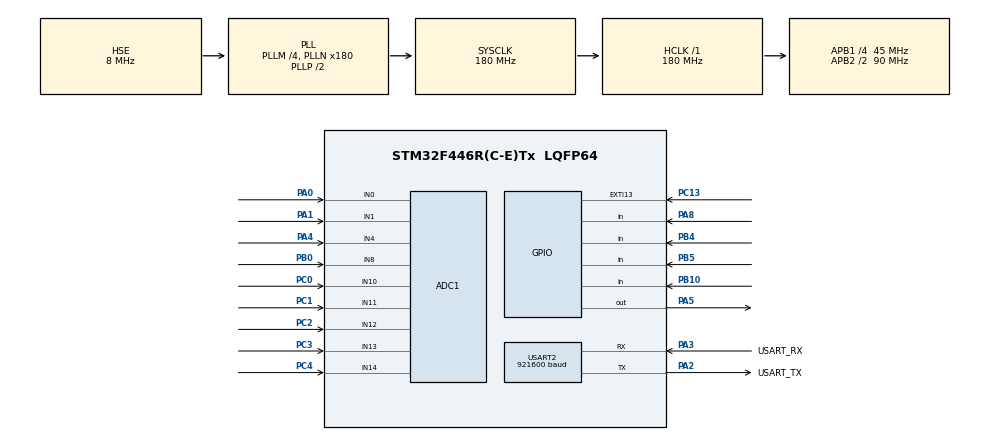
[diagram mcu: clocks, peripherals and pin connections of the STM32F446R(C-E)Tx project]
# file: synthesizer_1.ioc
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ADC1.Channel-0\#ChannelRegularConversion=ADC_CHANNEL_0
ADC1.Channel-1\#ChannelRegularConversion=ADC_CHANNEL_1
ADC1.Channel-2\#ChannelRegularConversion=ADC_CHANNEL_4
ADC1.Channel-3\#ChannelRegularConversion=ADC_CHANNEL_8
ADC1.Channel-4\#ChannelRegularConversion=ADC_CHANNEL_11
ADC1.Channel-5\#ChannelRegularConversion=ADC_CHANNEL_10
ADC1.Channel-6\#ChannelRegularConversion=ADC_CHANNEL_12
ADC1.Channel-7\#ChannelRegularConversion=ADC_CHANNEL_13
ADC1.Channel-8\#ChannelRegularConversion=ADC_CHANNEL_14
ADC1.NbrOfConversion=9
ADC1.NbrOfConversionFlag=1
ADC1.Rank-0\#ChannelRegularConversion=1
ADC1.Rank-1\#ChannelRegularConversion=2
ADC1.Rank-2\#ChannelRegularConversion=3
ADC1.Rank-3\#ChannelRegularConversion=4
ADC1.Rank-4\#ChannelRegularConversion=5
ADC1.Rank-5\#ChannelRegularConversion=6
ADC1.Rank-6\#ChannelRegularConversion=7
ADC1.Rank-7\#ChannelRegularConversion=8
ADC1.Rank-8\#ChannelRegularConversion=9
ADC1.SamplingTime-0\#ChannelRegularConversion=ADC_SAMPLETIME_480CYCLES
ADC1.SamplingTime-1\#ChannelRegularConversion=ADC_SAMPLETIME_480CYCLES
ADC1.SamplingTime-2\#ChannelRegularConversion=ADC_SAMPLETIME_480CYCLES
ADC1.SamplingTime-3\#ChannelRegularConversion=ADC_SAMPLETIME_480CYCLES
ADC1.SamplingTime-4\#ChannelRegularConversion=ADC_SAMPLETIME_480CYCLES
ADC1.SamplingTime-5\#ChannelRegularConversion=ADC_SAMPLETIME_480CYCLES
ADC1.SamplingTime-6\#ChannelRegularConversion=ADC_SAMPLETIME_480CYCLES
ADC1.SamplingTime-7\#ChannelRegularConversion=ADC_SAMPLETIME_480CYCLES
ADC1.SamplingTime-8\#ChannelRegularConversion=ADC_SAMPLETIME_480CYCLES
ADC1.ScanConvMode=ENABLE
ADC1.master=1
Dma.ADC1.0.Direction=DMA_PERIPH_TO_MEMORY
Dma.ADC1.0.FIFOMode=DMA_FIFOMODE_DISABLE
Dma.ADC1.0.Instance=DMA2_Stream0
Dma.ADC1.0.MemDataAlignment=DMA_MDATAALIGN_HALFWORD
Dma.ADC1.0.MemInc=DMA_MINC_ENABLE
Dma.ADC1.0.Mode=DMA_NORMAL
Dma.ADC1.0.PeriphDataAlignment=DMA_PDATAALIGN_HALFWORD
Dma.ADC1.0.PeriphInc=DMA_PINC_DISABLE
Dma.ADC1.0.Priority=DMA_PRIORITY_LOW
Dma.Request0=ADC1
Dma.Request1=USART2_TX
Dma.USART2_TX.1.Direction=DMA_MEMORY_TO_PERIPH
Dma.USART2_TX.1.FIFOMode=DMA_FIFOMODE_DISABLE
Dma.USART2_TX.1.Instance=DMA1_Stream6
Dma.USART2_TX.1.MemDataAlignment=DMA_MDATAALIGN_BYTE
Dma.USART2_TX.1.MemInc=DMA_MINC_ENABLE
Dma.USART2_TX.1.Mode=DMA_NORMAL
Dma.USART2_TX.1.PeriphDataAlignment=DMA_PDATAALIGN_BYTE
Dma.USART2_TX.1.PeriphInc=DMA_PINC_DISABLE
Dma.USART2_TX.1.Priority=DMA_PRIORITY_LOW
Mcu.Family=STM32F4
Mcu.Name=STM32F446R(C-E)Tx
Mcu.Package=LQFP64
NUCLEO-F446RE.BUTTON=1
NUCLEO-F446RE.LD1=true
NVIC.DMA1_Stream6_IRQn=true\:0\:0\:false\:false\:true\:false\:true\:true
NVIC.DMA2_Stream0_IRQn=true\:0\:0\:false\:false\:true\:false\:true\:true
NVIC.EXTI15_10_IRQn=true\:0\:0\:false\:false\:true\:false\:true\:true
NVIC.PriorityGroup=NVIC_PRIORITYGROUP_0
NVIC.TIM6_DAC_IRQn=true\:0\:0\:false\:false\:true\:true\:true\:true
NVIC.USART2_IRQn=true\:0\:0\:false\:false\:true\:true\:true\:true
PA0-WKUP.Signal=ADCx_IN0
PA1.Signal=ADCx_IN1
PA13.GPIO_Label=TMS
PA13.Signal=SYS_JTMS-SWDIO
PA14.GPIO_Label=TCK
PA14.Signal=SYS_JTCK-SWCLK
PA2.GPIO_Label=USART_TX
PA2.Mode=Asynchronous
PA2.Signal=USART2_TX
PA3.GPIO_Label=USART_RX
PA3.Mode=Asynchronous
PA3.Signal=USART2_RX
PA4.Signal=ADCx_IN4
PA5.Signal=GPIO_Output
PA8.GPIO_PuPd=GPIO_PULLUP
PA8.Signal=GPIO_Input
PB0.Signal=ADCx_IN8
PB10.GPIO_PuPd=GPIO_PULLUP
PB10.Signal=GPIO_Input
PB3.GPIO_Label=SWO
PB3.Signal=SYS_JTDO-SWO
PB4.GPIO_PuPd=GPIO_PULLUP
PB4.Signal=GPIO_Input
PB5.GPIO_PuPd=GPIO_PULLUP
PB5.Signal=GPIO_Input
PC0.Signal=ADCx_IN10
PC1.Signal=ADCx_IN11
PC13.Signal=GPXTI13
PC14-OSC32_IN.Signal=RCC_OSC32_IN
PC15-OSC32_OUT.Signal=RCC_OSC32_OUT
PC2.Signal=ADCx_IN12
PC3.Signal=ADCx_IN13
PC4.Signal=ADCx_IN14
PH0-OSC_IN.Mode=HSE-External-Clock-Source
PH0-OSC_IN.Signal=RCC_OSC_IN
PH1-OSC_OUT.Mode=HSE-External-Clock-Source
PH1-OSC_OUT.Signal=RCC_OSC_OUT
ProjectManager.HeapSize=0x200
ProjectManager.StackSize=0x400
ProjectManager.TargetToolchain=CMake
RCC.AHBFreq_Value=180000000
RCC.APB1CLKDivider=RCC_HCLK_DIV4
RCC.APB1Freq_Value=45000000
RCC.APB1TimFreq_Value=90000000
RCC.APB2CLKDivider=RCC_HCLK_DIV2
RCC.APB2Freq_Value=90000000
RCC.APB2TimFreq_Value=180000000
RCC.CortexFreq_Value=180000000
RCC.FLatency-AdvancedSettings=FLASH_LATENCY_5
RCC.HCLKFreq_Value=180000000
RCC.HSE_VALUE=8000000
RCC.HSI_VALUE=16000000
RCC.LSE_VALUE=32768
RCC.PLLM=4
RCC.PLLN=180
RCC.PLLSourceVirtual=RCC_PLLSOURCE_HSE
RCC.SYSCLKFreq_VALUE=180000000
RCC.SYSCLKSource=RCC_SYSCLKSOURCE_PLLCLK
RCC.USBFreq_Value=180000000
RCC.VCOOutputFreq_Value=360000000
SH.ADCx_IN0.0=ADC1_IN0,IN0
SH.ADCx_IN1.0=ADC1_IN1,IN1
SH.ADCx_IN10.0=ADC1_IN10,IN10
SH.ADCx_IN11.0=ADC1_IN11,IN11
SH.ADCx_IN12.0=ADC1_IN12,IN12
SH.ADCx_IN13.0=ADC1_IN13,IN13
SH.ADCx_IN14.0=ADC1_IN14,IN14
SH.ADCx_IN4.0=ADC1_IN4,IN4
SH.ADCx_IN8.0=ADC1_IN8,IN8
TIM6.Period=4081
USART2.BaudRate=921600
USART2.VirtualMode=VM_ASYNC
VP_NUCLEO-F446RE_VS_BSP_COMMON.Mode=COMMON
VP_TIM6_VS_ClockSourceINT.Mode=Enable_Timer
board=NUCLEO-F446RE

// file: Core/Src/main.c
/* USER CODE BEGIN Header */
/**
  ******************************************************************************
  * @file           : main.c
  * @brief          : Main program body
  ******************************************************************************
  * @attention
  *
  * Copyright (c) 2026 STMicroelectronics.
  * All rights reserved.
  *
  * This software is licensed under terms that can be found in the LICENSE file
  * in the root directory of this software component.
  * If no LICENSE file comes with this software, it is provided AS-IS.
  *
  ******************************************************************************
  */
/* USER CODE END Header */
#include "main.h"

ADC_HandleTypeDef hadc1;
DMA_HandleTypeDef hdma_adc1;

TIM_HandleTypeDef htim6;

UART_HandleTypeDef huart2;
DMA_HandleTypeDef hdma_usart2_tx;

void SystemClock_Config(void);
static void MX_GPIO_Init(void);
static void MX_DMA_Init(void);
static void MX_ADC1_Init(void);
static void MX_TIM6_Init(void);
static void MX_USART2_UART_Init(void);
/* USER CODE BEGIN PFP */
void synth_init(void);
void synth_loop(void);

/* USER CODE END PFP */

int main(void)
{

  /* MCU Configuration--------------------------------------------------------*/

  /* Reset of all peripherals, Initializes the Flash interface and the Systick. */
  HAL_Init();

  /* Configure the system clock */
  SystemClock_Config();

  /* Initialize all configured peripherals */
  MX_GPIO_Init();
  MX_DMA_Init();
  MX_ADC1_Init();
  MX_TIM6_Init();
  MX_USART2_UART_Init();
  /* USER CODE BEGIN 2 */
  synth_init();

  /* USER CODE END 2 */

  /* Initialize leds */
  BSP_LED_Init(LED2);

  /* Initialize USER push-button, will be used to trigger an interrupt each time it's pressed.*/
  BSP_PB_Init(BUTTON_USER, BUTTON_MODE_EXTI);

  /* Infinite loop */
  while (1)
  {

    /* USER CODE BEGIN 3 */
    synth_loop();
  }
  /* USER CODE END 3 */
}

void SystemClock_Config(void)
{
  RCC_OscInitTypeDef RCC_OscInitStruct = {0};
  RCC_ClkInitTypeDef RCC_ClkInitStruct = {0};

  /** Configure the main internal regulator output voltage
  */
  __HAL_RCC_PWR_CLK_ENABLE();
  __HAL_PWR_VOLTAGESCALING_CONFIG(PWR_REGULATOR_VOLTAGE_SCALE1);

  /** Initializes the RCC Oscillators according to the specified parameters
  * in the RCC_OscInitTypeDef structure.
  */
  RCC_OscInitStruct.OscillatorType = RCC_OSCILLATORTYPE_HSE;
  RCC_OscInitStruct.HSEState = RCC_HSE_BYPASS;
  RCC_OscInitStruct.PLL.PLLState = RCC_PLL_ON;
  RCC_OscInitStruct.PLL.PLLSource = RCC_PLLSOURCE_HSE;
  RCC_OscInitStruct.PLL.PLLM = 4;
  RCC_OscInitStruct.PLL.PLLN = 180;
  RCC_OscInitStruct.PLL.PLLP = RCC_PLLP_DIV2;
  RCC_OscInitStruct.PLL.PLLQ = 2;
  RCC_OscInitStruct.PLL.PLLR = 2;
  if (HAL_RCC_OscConfig(&RCC_OscInitStruct) != HAL_OK)
  {
    Error_Handler();
  }

  /** Activate the Over-Drive mode
  */
  if (HAL_PWREx_EnableOverDrive() != HAL_OK)
  {
    Error_Handler();
  }

  /** Initializes the CPU, AHB and APB buses clocks
  */
  RCC_ClkInitStruct.ClockType = RCC_CLOCKTYPE_HCLK|RCC_CLOCKTYPE_SYSCLK
                              |RCC_CLOCKTYPE_PCLK1|RCC_CLOCKTYPE_PCLK2;
  RCC_ClkInitStruct.SYSCLKSource = RCC_SYSCLKSOURCE_PLLCLK;
  RCC_ClkInitStruct.AHBCLKDivider = RCC_SYSCLK_DIV1;
  RCC_ClkInitStruct.APB1CLKDivider = RCC_HCLK_DIV4;
  RCC_ClkInitStruct.APB2CLKDivider = RCC_HCLK_DIV2;

  if (HAL_RCC_ClockConfig(&RCC_ClkInitStruct, FLASH_LATENCY_5) != HAL_OK)
  {
    Error_Handler();
  }
}

static void MX_ADC1_Init(void)
{

  ADC_ChannelConfTypeDef sConfig = {0};

  /** Configure the global features of the ADC (Clock, Resolution, Data Alignment and number of conversion)
  */
  hadc1.Instance = ADC1;
  hadc1.Init.ClockPrescaler = ADC_CLOCK_SYNC_PCLK_DIV4;
  hadc1.Init.Resolution = ADC_RESOLUTION_12B;
  hadc1.Init.ScanConvMode = ENABLE;
  hadc1.Init.ContinuousConvMode = DISABLE;
  hadc1.Init.DiscontinuousConvMode = DISABLE;
  hadc1.Init.ExternalTrigConvEdge = ADC_EXTERNALTRIGCONVEDGE_NONE;
  hadc1.Init.ExternalTrigConv = ADC_SOFTWARE_START;
  hadc1.Init.DataAlign = ADC_DATAALIGN_RIGHT;
  hadc1.Init.NbrOfConversion = 9;
  hadc1.Init.DMAContinuousRequests = DISABLE;
  hadc1.Init.EOCSelection = ADC_EOC_SINGLE_CONV;
  if (HAL_ADC_Init(&hadc1) != HAL_OK)
  {
    Error_Handler();
  }

  /** Configure for the selected ADC regular channel its corresponding rank in the sequencer and its sample time.
  */
  sConfig.Channel = ADC_CHANNEL_0;
  sConfig.Rank = 1;
  sConfig.SamplingTime = ADC_SAMPLETIME_480CYCLES;
  if (HAL_ADC_ConfigChannel(&hadc1, &sConfig) != HAL_OK)
  {
    Error_Handler();
  }

  /** Configure for the selected ADC regular channel its corresponding rank in the sequencer and its sample time.
  */
  sConfig.Channel = ADC_CHANNEL_1;
  sConfig.Rank = 2;
  if (HAL_ADC_ConfigChannel(&hadc1, &sConfig) != HAL_OK)
  {
    Error_Handler();
  }

  /** Configure for the selected ADC regular channel its corresponding rank in the sequencer and its sample time.
  */
  sConfig.Channel = ADC_CHANNEL_4;
  sConfig.Rank = 3;
  if (HAL_ADC_ConfigChannel(&hadc1, &sConfig) != HAL_OK)
  {
    Error_Handler();
  }

  /** Configure for the selected ADC regular channel its corresponding rank in the sequencer and its sample time.
  */
  sConfig.Channel = ADC_CHANNEL_8;
  sConfig.Rank = 4;
  if (HAL_ADC_ConfigChannel(&hadc1, &sConfig) != HAL_OK)
  {
    Error_Handler();
  }

  /** Configure for the selected ADC regular channel its corresponding rank in the sequencer and its sample time.
  */
  sConfig.Channel = ADC_CHANNEL_11;
  sConfig.Rank = 5;
  if (HAL_ADC_ConfigChannel(&hadc1, &sConfig) != HAL_OK)
  {
    Error_Handler();
  }

  /** Configure for the selected ADC regular channel its corresponding rank in the sequencer and its sample time.
  */
  sConfig.Channel = ADC_CHANNEL_10;
  sConfig.Rank = 6;
  if (HAL_ADC_ConfigChannel(&hadc1, &sConfig) != HAL_OK)
  {
    Error_Handler();
  }
  sConfig.Channel = ADC_CHANNEL_12;
  sConfig.Rank = 7;
  if (HAL_ADC_ConfigChannel(&hadc1, &sConfig) != HAL_OK)
  {
    Error_Handler();
  }

  sConfig.Channel = ADC_CHANNEL_13;
  sConfig.Rank = 8;
  if (HAL_ADC_ConfigChannel(&hadc1, &sConfig) != HAL_OK)
  {
    Error_Handler();
  }

  sConfig.Channel = ADC_CHANNEL_14;
  sConfig.Rank = 9;
  if (HAL_ADC_ConfigChannel(&hadc1, &sConfig) != HAL_OK)
  {
    Error_Handler();
  }

}

static void MX_TIM6_Init(void)
{

  TIM_MasterConfigTypeDef sMasterConfig = {0};

  htim6.Instance = TIM6;
  htim6.Init.Prescaler = 0;
  htim6.Init.CounterMode = TIM_COUNTERMODE_UP;
  htim6.Init.Period = 4081;
  htim6.Init.AutoReloadPreload = TIM_AUTORELOAD_PRELOAD_DISABLE;
  if (HAL_TIM_Base_Init(&htim6) != HAL_OK)
  {
    Error_Handler();
  }
  sMasterConfig.MasterOutputTrigger = TIM_TRGO_RESET;
  sMasterConfig.MasterSlaveMode = TIM_MASTERSLAVEMODE_DISABLE;
  if (HAL_TIMEx_MasterConfigSynchronization(&htim6, &sMasterConfig) != HAL_OK)
  {
    Error_Handler();
  }

}

static void MX_USART2_UART_Init(void)
{

  huart2.Instance = USART2;
  huart2.Init.BaudRate = 921600;
  huart2.Init.WordLength = UART_WORDLENGTH_8B;
  huart2.Init.StopBits = UART_STOPBITS_1;
  huart2.Init.Parity = UART_PARITY_NONE;
  huart2.Init.Mode = UART_MODE_TX_RX;
  huart2.Init.HwFlowCtl = UART_HWCONTROL_NONE;
  huart2.Init.OverSampling = UART_OVERSAMPLING_16;
  if (HAL_UART_Init(&huart2) != HAL_OK)
  {
    Error_Handler();
  }

}

static void MX_DMA_Init(void)
{

  /* DMA controller clock enable */
  __HAL_RCC_DMA2_CLK_ENABLE();
  __HAL_RCC_DMA1_CLK_ENABLE();

  /* DMA interrupt init */
  /* DMA1_Stream6_IRQn interrupt configuration */
  HAL_NVIC_SetPriority(DMA1_Stream6_IRQn, 0, 0);
  HAL_NVIC_EnableIRQ(DMA1_Stream6_IRQn);
  /* DMA2_Stream0_IRQn interrupt configuration */
  HAL_NVIC_SetPriority(DMA2_Stream0_IRQn, 0, 0);
  HAL_NVIC_EnableIRQ(DMA2_Stream0_IRQn);

}

static void MX_GPIO_Init(void)
{
  GPIO_InitTypeDef GPIO_InitStruct = {0};

  /* GPIO Ports Clock Enable */
  __HAL_RCC_GPIOC_CLK_ENABLE();
  __HAL_RCC_GPIOH_CLK_ENABLE();
  __HAL_RCC_GPIOA_CLK_ENABLE();
  __HAL_RCC_GPIOB_CLK_ENABLE();

  /*Configure GPIO pins : PB10 PB4 PB5 */
  GPIO_InitStruct.Pin = GPIO_PIN_10|GPIO_PIN_4|GPIO_PIN_5;
  GPIO_InitStruct.Mode = GPIO_MODE_INPUT;
  GPIO_InitStruct.Pull = GPIO_PULLUP;
  HAL_GPIO_Init(GPIOB, &GPIO_InitStruct);

  /*Configure GPIO pin : PA8 */
  GPIO_InitStruct.Pin = GPIO_PIN_8;
  GPIO_InitStruct.Mode = GPIO_MODE_INPUT;
  GPIO_InitStruct.Pull = GPIO_PULLUP;
  HAL_GPIO_Init(GPIOA, &GPIO_InitStruct);

}

void Error_Handler(void)
{
  __disable_irq();
  while (1)
  {
  }
}
